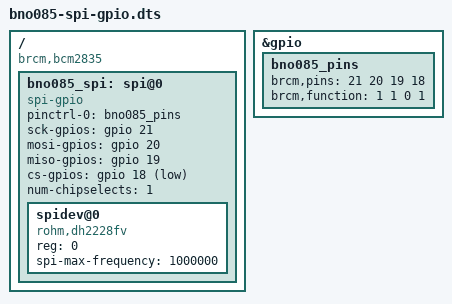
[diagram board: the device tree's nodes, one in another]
/dts-v1/;
/plugin/;

/* Bit-banged SPI (mode 3 capable) for the BNO085 on the SPI1 pins:
 * SCK=GPIO21, MOSI=GPIO20, MISO=GPIO19, CS0=GPIO18 (active low). Appears as /dev/spidev0.0
 * (the aux SPI1 controller cannot do CPHA=1, which the BNO08x requires). */
/ {
	compatible = "brcm,bcm2835";

	fragment@0 {
		target = <&gpio>;
		__overlay__ {
			bno085_pins: bno085_pins {
				brcm,pins = <21 20 19 18>;
				brcm,function = <1 1 0 1>; /* out out in out */
			};
		};
	};

	fragment@1 {
		target-path = "/";
		__overlay__ {
			bno085_spi: spi@0 {
				compatible = "spi-gpio";
				#address-cells = <1>;
				#size-cells = <0>;
				pinctrl-names = "default";
				pinctrl-0 = <&bno085_pins>;
				sck-gpios = <&gpio 21 0>;
				mosi-gpios = <&gpio 20 0>;
				miso-gpios = <&gpio 19 0>;
				cs-gpios = <&gpio 18 1>; /* GPIO_ACTIVE_LOW */
				num-chipselects = <1>;
				status = "okay";

				spidev@0 {
					compatible = "rohm,dh2228fv";
					reg = <0>;
					spi-max-frequency = <1000000>;
					status = "okay";
				};
			};
		};
	};
};
